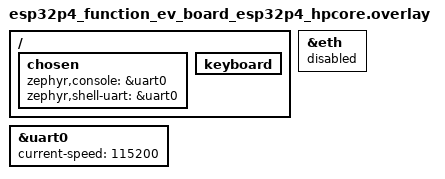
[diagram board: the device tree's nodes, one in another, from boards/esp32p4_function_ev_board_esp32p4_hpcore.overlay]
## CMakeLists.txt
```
cmake_minimum_required(VERSION 3.20.0)

find_package(Zephyr REQUIRED HINTS $ENV{ZEPHYR_BASE})
project(app)

include(${CMAKE_CURRENT_LIST_DIR}/../lib/fs/sysfs/cmake/sysfs.cmake)

sysfs_generate(
    ROOT "${CMAKE_CURRENT_SOURCE_DIR}/assets"
)

if(CONFIG_BOARD_NATIVE_SIM AND CONFIG_PICOLIBC)
    target_sources(app PRIVATE
        ${ZEPHYR_PICOLIBC_MODULE_DIR}/newlib/libc/machine/x86/setjmp.S
    )
endif()

target_sources(app 
  PRIVATE 
    src/main.c 
    src/devfs.c 
    src/render.c 
    src/net/connection.c 
    src/net/network.c
    src/corelib/corelib.c 
    src/corelib/windowlib.c 
)
```

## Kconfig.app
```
# Must be called "Kconfig.<something>" otherwise Zephyr considers 
# this directory as root and does not include ./lib/ !

config LUA_HEAP_SIZE
  int "Heap Lua can consume"
  default 131072  # 128kB

config SYSFS_MAX_FDS
  int 
  default 8
```

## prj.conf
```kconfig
CONFIG_STDOUT_CONSOLE=y

CONFIG_HEAP_MEM_POOL_SIZE=16384

CONFIG_DISPLAY=y

CONFIG_LOG=y

# LIBRARIES
CONFIG_SERIAL=y
CONFIG_LIBTSM=y
CONFIG_FONTS=y
CONFIG_WCWIDTH=y
CONFIG_KEYMAP=y
CONFIG_LIBUTF8=y
CONFIG_MINITELNET=y
CONFIG_WINDOW=y

CONFIG_DEBUG=y
CONFIG_INPUT=y
CONFIG_LIBTSM_LOG_LEVEL_DBG=y

CONFIG_NETWORKING=y
CONFIG_NET_SOCKETS=y
CONFIG_NET_TCP=y
CONFIG_NET_IPV4=y

CONFIG_NET_DHCPV4=y

CONFIG_EVENTS=y
```

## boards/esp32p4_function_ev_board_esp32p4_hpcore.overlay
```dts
/ {
   chosen {
        zephyr,console = &uart0;
        zephyr,shell-uart = &uart0;
   };

   keyboard {
        status = "okay";
   };
};

&uart0 {
    status = "okay";
    current-speed = <115200>;
};

&eth {
    status = "disabled";
};
```

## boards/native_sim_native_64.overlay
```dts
/ {
    keyboard {
        compatible = "zephyr,native-linux-evdev";
    };
};

&sdl_dc {
    status = "okay";
    width = <1024>;
    height = <600>;
};

&uart1 {
    status = "okay";
};
```

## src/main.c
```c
#include "corelib/corelib.h"
#include "internal.h"
#include "window/layout.h"
#include "zephyr/device.h"
#include "zephyr/input/input.h"

#include <devfs/devfs.h>
#include <lauxlib.h>
#include <lualib.h>
#include <sysfs/sysfs.h>
#include <termlet_fs.h>
#include <zephyr/drivers/display.h>
#include <zephyr/fs/fs.h>
#include <zephyr/kernel.h>
#include <zephyr/logging/log.h>
#include <zephyr/sys/util.h>
LOG_MODULE_REGISTER(app);

#define HAS_FLAGS(value, flags) (((value) & (flags)) == (flags))

const struct font *regular_font;
const struct font *bold_font;
const struct font *italic_font;
const struct font *bolditalic_font;

extern const struct devfs_entry devices[];
extern const struct sysfs_entry sysfs_root;

static struct sysfs_fs sysfs_data = {
	.root = &sysfs_root,
};

struct fs_mount_t mountpoints[] = {
	{ .type = FS_SYSFS, .mnt_point = "/sys", .fs_data = &sysfs_data },
	{ .type = FS_DEVFS, .mnt_point = "/dev", .fs_data = (void *) devices }
};

K_HEAP_DEFINE(lua_heap, CONFIG_LUA_HEAP_SIZE);

static void *lua_alloc(void *ud, void *ptr, size_t osize, size_t nsize) {
	struct k_heap *heap = ud;

	ARG_UNUSED(osize);

	if (nsize == 0) {
		k_heap_free(heap, ptr);
		return NULL;
	}

	return k_heap_realloc(heap, ptr, nsize, K_NO_WAIT);
}

static int walk_tree(const char *path, unsigned depth) {
	struct fs_dir_t dir;
	struct fs_dirent entry;
	char child[256];
	int ret;

	fs_dir_t_init(&dir);

	ret = fs_opendir(&dir, path);
	if (ret < 0) {
		LOG_ERR("opendir(%s): %d", path, ret);
		return ret;
	}

	for (;;) {
		ret = fs_readdir(&dir, &entry);
		if (ret < 0) {
			LOG_ERR("readdir(%s): %d", path, ret);
			break;
		}

		if (entry.name[0] == '\0')
			break;

		LOG_INF("%*s%s%s %d",
		        (int) (depth * 2), "",
		        entry.name,
		        entry.type == FS_DIR_ENTRY_DIR ? "/" : "",
		        entry.size);

		ret = snprintf(child, sizeof(child),
		               "%s%s%s",
		               path,
		               path[strlen(path) - 1] == '/' ? "" : "/",
		               entry.name);

		if (ret < 0 || ret >= (int) sizeof(child)) {
			LOG_ERR("path too long: %s/%s",
			        path, entry.name);
			ret = -ENAMETOOLONG;
			break;
		}

		if (entry.type == FS_DIR_ENTRY_DIR) {
			ret = walk_tree(child, depth + 1);
			if (ret < 0)
				break;
		}
	}

	{
		int close_ret = fs_closedir(&dir);

		if (ret == 0 && close_ret < 0)
			ret = close_ret;
	}

	return ret;
}

void init_mount() {
	LOG_INF("mount points");
	int ret;
	for (int i = 0; i < (int) ARRAY_SIZE(mountpoints); i++) {
		if ((ret = fs_mount(&mountpoints[i])) != 0) {
			LOG_ERR("unable to mount %s: %d %s", mountpoints[i].mnt_point, ret, strerror(-ret));
		}
	}

	walk_tree("/", 0);
}

static int openlibs(lua_State *L) {
	luaL_openselectedlibs(
	    L,
	    LUA_GLIBK |
	        LUA_LOADLIBK |
	        LUA_STRLIBK |
	        LUA_UTF8LIBK |
	        LUA_TABLIBK |
	        LUA_MATHLIBK |
	        LUA_IOLIBK,
	    1);

	corelib_register(L);

	return 0;
}

const struct font *get_font(const char *name, const char *style, int size, const struct font *fallback) {
	for (size_t i = 0; i < font_count; i++) {
		if (strcmp(fonts[i]->name, name) == 0 && strcmp(fonts[i]->style, style) == 0 && fonts[i]->size == size) {
			return fonts[i];
		}
	}
	return fallback;
}

void init_fonts() {
	regular_font = get_font("Go Mono", "Regular", 14, NULL);
	bold_font = get_font("Go Mono", "Bold", 14, regular_font);
	italic_font = get_font("Go Mono", "Italic", 14, bold_font);
	bolditalic_font = get_font("Go Mono", "Bold Italic", 14, italic_font);
}

lua_State *init_lua() {
	lua_State *L = lua_newstate(lua_alloc, &lua_heap, 42);
	if (L == NULL) {
		LOG_ERR("cannot create Lua state");
		return NULL;
	}

	lua_pushcfunction(L, openlibs);
	int status = lua_pcall(L, 0, 0, 0);
	if (status != LUA_OK) {
		LOG_ERR("cannot initialize Lua: %s", lua_tostring(L, -1));
		lua_close(L);
		return NULL;
	}

	status = luaL_dofile(L, "/sys/init.lua");
	if (status != LUA_OK) {
		LOG_ERR("lua error: %s", lua_tostring(L, -1));
		lua_pop(L, 1);
	}

	LOG_INF("Lua initalized");
	return L;
}

void draw_char(uint16_t x, uint16_t y, struct win_char ch, void *userdata) {
	struct renderer *r = userdata;
	const struct font *font = regular_font;
	if (HAS_FLAGS(ch.attr, WIN_CHAR_BOLD | WIN_CHAR_ITALIC)) {
		font = bolditalic_font;
	} else if (HAS_FLAGS(ch.attr, WIN_CHAR_BOLD)) {
		font = bold_font;
	} else if (HAS_FLAGS(ch.attr, WIN_CHAR_ITALIC)) {
		font = italic_font;
	}
	draw_glyph(r, ch.code, x, y, font, ch.bg, ch.fg);
}

void commit(void *userdata) {
	struct renderer *r = userdata;
	draw_commit(r);
}

void input_handle(struct input_event *evt, void *userdata) {
	win_layout_input(&layout, evt);
}

int main() {
	init_mount();
	init_fonts();

	struct renderer renderer = { 0 };
	renderer.columns = DISPLAY_WIDTH / regular_font->width;
	renderer.rows = DISPLAY_HEIGHT / regular_font->height;
	renderer.display = DEVICE_DT_GET(DT_CHOSEN(zephyr_display));


	int ret = display_set_pixel_format(renderer.display, PIXEL_FORMAT_RGB_565);
	if (ret < 0) {
		LOG_INF("Unable to select RGB565: %d", ret);
		return 0;
	}
	ret = display_blanking_off(renderer.display);
	if (ret < 0)
		LOG_INF("display_blanking_off failed: %d", ret);

	memset(&layout, 0, sizeof(layout));
	layout.bounds.x1 = renderer.columns;
	layout.bounds.y1 = renderer.rows;
	layout.draw_char = draw_char;
	layout.commit = commit;
	layout.userdata = &renderer;

	lua_State *L = init_lua();

#define FPS      60
#define FRAME_US (1000000 / FPS)

	int64_t next = k_uptime_get() * 1000;

	for (;;) {
		win_layout_render(&layout);

		next += FRAME_US;

		int64_t now = k_uptime_get() * 1000;
		if (next > now)
			k_usleep(next - now);
	}

	lua_close(L);
	return 0;
}

INPUT_CALLBACK_DEFINE(NULL, input_handle, NULL);
```

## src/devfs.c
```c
#include <devfs/devfs.h>
#include <sys/types.h>
#include <termlet_fs.h>
#include <zephyr/devicetree.h>
#include <zephyr/drivers/uart.h>
#include <zephyr/kernel.h>

static int uart_open(const struct devfs_entry *entry,
                     struct fs_file_t *file,
                     fs_mode_t flags) {

	const struct device *dev = entry->userdata;
	if (!device_is_ready(dev))
		return -ENODEV;

	return 0;
}

static ssize_t uart_write(const struct devfs_entry *entry,
                          struct fs_file_t *file,
                          const void *ptr,
                          size_t size) {
	ARG_UNUSED(file);

	const struct device *dev = entry->userdata;
	const uint8_t *buf = ptr;
	size_t written = 0;

	while (written < size) {
		uart_poll_out(dev, buf[written]);
		written++;
	}

	return (ssize_t) written;
}

static ssize_t uart_read(const struct devfs_entry *entry,
                         struct fs_file_t *file,
                         void *ptr,
                         size_t size)
{
	ARG_UNUSED(file);

	const struct device *dev = entry->userdata;
	uint8_t *buf = ptr;

	if (size == 0)
		return 0;

	size_t n = 0;

	/* Block until at least one byte arrives. */
	while (uart_poll_in(dev, &buf[n]) == -1)
		k_sleep(K_MSEC(1));

	n++;

	/* Drain all immediately available bytes. */
	while (n < size) {
		int ret = uart_poll_in(dev, &buf[n]);

		if (ret == -1)
			break;

		if (ret < 0)
			return n > 0 ? (ssize_t)n : ret;

		n++;
	}

	return (ssize_t)n;
}

static const struct devfs_ops uart_ops = {
	.open = uart_open,
	.write = uart_write,
	.read = uart_read,
};


const struct devfs_entry devices[] = {

#if DT_HAS_CHOSEN(zephyr_console)
#	define STDIO_DEVICE DEVICE_DT_GET(DT_CHOSEN(zephyr_console))
	{
	    .name = "stdin",
	    .ops = &uart_ops,
	    .userdata = (void *) STDIO_DEVICE,
	},
	{
	    .name = "stdout",
	    .ops = &uart_ops,
	    .userdata = (void *) STDIO_DEVICE,
	},
	{
	    .name = "stderr",
	    .ops = &uart_ops,
	    .userdata = (void *) STDIO_DEVICE,
	},
#endif

	{ 0 }
};
```

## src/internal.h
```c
#pragma once

#include <fonts.h>
#include <window/geom.h>
#include <zephyr/fs/fs.h>

#define DISPLAY_WIDTH  DT_PROP(DT_CHOSEN(zephyr_display), width)
#define DISPLAY_HEIGHT DT_PROP(DT_CHOSEN(zephyr_display), height)

struct renderer {
	const struct device *display;
	struct win_rect dirty;

	unsigned int columns;
	unsigned int rows;
};

void draw_glyph(struct renderer *rend, uint32_t codepoint, uint16_t x, uint16_t y, const struct font *font, uint16_t fg, uint16_t bg);
void draw_commit(struct renderer *rend);

int sysfs_register();
```

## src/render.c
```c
#include "internal.h"
#include "zephyr/sys/printk.h"

#include <stdint.h>
#include <window/geom.h>
#include <zephyr/devicetree.h>
#include <zephyr/drivers/display.h>


static uint16_t framebuffer[DISPLAY_WIDTH * DISPLAY_HEIGHT];

static inline uint16_t blend_rgb565(uint16_t bg, uint16_t fg, uint8_t coverage) {
	uint32_t br = (bg >> 11) & 0x1f;
	uint32_t bgc = (bg >> 5) & 0x3f;
	uint32_t bb = bg & 0x1f;

	uint32_t fr = (fg >> 11) & 0x1f;
	uint32_t fgc = (fg >> 5) & 0x3f;
	uint32_t fb = fg & 0x1f;

	uint32_t r = (br * (15 - coverage) + fr * coverage) / 15;
	uint32_t g = (bgc * (15 - coverage) + fgc * coverage) / 15;
	uint32_t b = (bb * (15 - coverage) + fb * coverage) / 15;

	return (uint16_t) ((r << 11) | (g << 5) | b);
}

void draw_glyph(struct renderer *rend, uint32_t codepoint, uint16_t x, uint16_t y, const struct font *font, uint16_t fg, uint16_t bg) {

	const uint8_t *glyph = font_get_glyph(font, codepoint);
	uint16_t colors[16];

	for (unsigned int i = 0; i < ARRAY_SIZE(colors); i++)
		colors[i] = blend_rgb565(bg, fg, i);

	for (unsigned int gy = 0; gy < font->height; gy++) {
		unsigned int py = y * font->height + gy;

		for (unsigned int gx = 0; gx < font->width; gx++) {
			unsigned int px = x * font->width + gx;

			uint8_t coverage = font_glyph_coverage(font, glyph, gx, gy);
			framebuffer[py * DISPLAY_WIDTH + px] = colors[coverage];
		}
	}

	struct win_rect drawn = {
		.x0 = x,
		.x1 = x + font->width,
		.y0 = y,
		.y1 = y + font->height,
	};

	win_rect_include_rect(&rend->dirty, drawn);
}

void draw_commit(struct renderer *rend) {
	struct display_buffer_descriptor desc = {
		.buf_size = DISPLAY_WIDTH * DISPLAY_HEIGHT,
		.width = DISPLAY_WIDTH,
		.height = DISPLAY_HEIGHT,
		.pitch = DISPLAY_WIDTH,
		.frame_incomplete = false,
	};

	display_write(rend->display, 0, 0, &desc, framebuffer);
}
```
